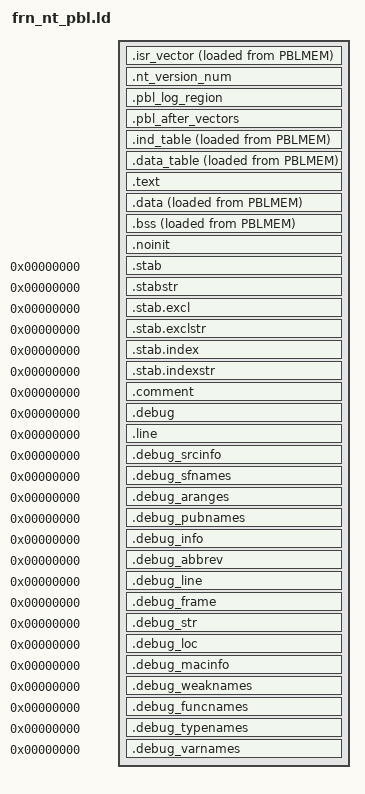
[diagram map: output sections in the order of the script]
/*
*/

/*
 * Memory Spaces Definitions.
 */


INCLUDE frn_nt_bl_cmn.ld



/*
 * Default linker script for Cortex-M
 *
 * To make use of the multi-region initialisations, define
 * OS_INCLUDE_STARTUP_INIT_MULTIPLE_RAM_SECTIONS for the _startup.c file.
 */

/*Neutrino OTP region address start*/
 __OTP_region_st_addr = ORIGIN(OTPMEM);
 __OTP_region_end_addr = ORIGIN(OTPMEM) + LENGTH(OTPMEM);
 __OTP_rfregion_st_addr = ORIGIN(OTPRFMEM);
 __OTP_rfregion_end_addr = ORIGIN(OTPRFMEM) + LENGTH(OTPRFMEM);

 /*RRAM main memory address space*/
 __rram_region_start_addr = ORIGIN(PBLMEM);
 __rram_region_end_address = ORIGIN(PBLMEM) + LENGTH(PBLMEM) + LENGTH(FDTMEM) + LENGTH(SBLAMEM) + LENGTH(RESERVED) + LENGTH(PBL_PATCH) + LENGTH(FSMEM) + LENGTH(CALMEM) + LENGTH(BDFMEM) + LENGTH(REGDBMEM) + LENGTH(RRAMMEM);

 /*FDT address space*/
 __fdt_reg_st_addr = ORIGIN(FDTMEM);
 __fdt_reg_end_addr = ORIGIN(FDTMEM) + LENGTH(FDTMEM);

/*PBL patch function start address*/
 __sec_patch_start = ORIGIN(PBL_PATCH);

/*
 * The '__stack' definition is required by crt0, do not remove it.
 */
_ln_PBL_stack__ = ORIGIN(PBL_RAM) + LENGTH(PBL_RAM);
__PBL_Stack_Size = 0x200 ;
_estack = _ln_PBL_stack__;

PROVIDE ( _PBL_Stack_Size = __PBL_Stack_Size ) ;

__PBL_Stack_Limit = _ln_PBL_stack__  - __PBL_Stack_Size ;

PROVIDE ( _PBL_Stack_Limit = __PBL_Stack_Limit ) ;

 /* config table in ram */
 __config_table = ORIGIN(CONFIG_TABLE);
 __config_table_size = LENGTH(CONFIG_TABLE);

/*
 * Default heap definitions.
 * The heap start immediately after the last statically allocated
 * .sbss/.noinit section, and extends up to the main stack limit.
 */
PROVIDE ( _Heap_Begin = _end_noinit ) ;
PROVIDE ( _Heap_Limit = _ln_PBL_stack__ - __PBL_Stack_Size ) ;


/*
 * The entry point is informative, for debuggers and simulators,
 * since the Cortex-M vector points to it anyway.
 */
ENTRY(nt_boot)


/* Sections Definitions */

SECTIONS
{
	/*
	* For Cortex-M devices, the beginning of the startup code is stored in
	* the .isr_vector section, which goes to FLASH.
	*/
	.isr_vector : ALIGN(4)
	{
		FILL(0xFF)
		__vectors_start = ABSOLUTE(.) ;
		KEEP(*(.pbl_isr_vector))     /* Interrupt vectors */

	} >PBL_RAM AT >PBLMEM

	_ln_RF_start_addr_isr__ = LOADADDR(.isr_vector);
	_ln_RAM_start_addr_isr__ = ADDR(.isr_vector);

	_ln_pbl_isr_size__ = SIZEOF(.isr_vector);

	.nt_version_num : ALIGN(4)
	{
		KEEP(*(.nt_version_num));
	} >PBLMEM

	.pbl_log_region : ALIGN(4)
	{
	    _ln_RAM_ferm_table_addr = ABSOLUTE(.);
        . += 8; /* 4 bytes extra space allocated as reserved */
		__PBL_log_start_addr__ = ABSOLUTE(.) ;
		. += 256 ;
		. = ALIGN(4);
	} > PBL_RAM

	.pbl_after_vectors : ALIGN(4)
	{
		/*
		* This section is here for convenience, to store the
		* startup code at the beginning of the flash area, hoping that
		* this will increase the readability of the listing.
		*/
		*(.pbl_after_vectors .pbl_after_vectors.*) /* Boot code and ISR */

		. = ALIGN(4);

	} >PBLMEM

	.ind_table : ALIGN(4)
	{
		/* This section is for PBL indirection table. This is loaded to RRAM and
		 * copied to RAM during startup.
		 */
		FILL(0xFF)
		__ind_table_start = ABSOLUTE(.) ;
		KEEP(*(.pbl_ind_table))

	} >PBL_RAM AT >PBLMEM

	_ln_RF_start_addr_ind__ = LOADADDR(.ind_table);
	_ln_RAM_start_addr_ind__ = ADDR(.ind_table);
	_ln_pbl_ind_size__ = SIZEOF(.ind_table);

	.data_table : ALIGN(4)
	{
		/* This section is for global data pointer table. This is loaded to RRAM
		 * and copied to RAM during startup.
		 */
		FILL(0xFF)
		__glb_data_table_start = ABSOLUTE(.) ;
		KEEP(*(.glb_data_table))     /* global data table*/

	} >PBL_RAM AT >PBLMEM

	_ln_RF_start_addr_glb_data__ = LOADADDR(.data_table);
	_ln_RAM_start_addr_glb_data__ = ADDR(.data_table);
	_ln_pbl_glb_data_size__ = SIZEOF(.data_table);


	/*
	* The program code is stored in the .text section,
	* which goes to FLASH.
	*/
	.text : ALIGN(4)
	{
		*(.text .text.*) /* all remaining code */
		*(.rodata .rodata.* .constdata .constdata.*) /* read-only data (constants) */
		*(vtable) /* C++ virtual tables */

		KEEP(*(.eh_frame*))

		/*
		* Stub sections generated by the linker, to glue together
		* ARM and Thumb code. .glue_7 is used for ARM code calling
		* Thumb code, and .glue_7t is used for Thumb code calling
		* ARM code. Apparently always generated by the linker, for some
		* architectures, so better leave them here.
		*/
		*(.glue_7)
		*(.glue_7t)

	} >PBLMEM

	/*
	* The initialised data section.
	*
	* The program executes knowing that the data is in the RAM
	* but the loader puts the initial values in the FLASH (inidata).
	* It is one task of the startup to copy the initial values from
	* FLASH to RAM.
	*/
	.data : ALIGN(4)
	{
		FILL(0xFF)

		/* This is used by the startup code to initialise the .data section */

		__data_start__ = . ;
		*(.data_begin .data_begin.*)
		*(.data .data.*)
		*(.data_end .data_end.*)
		. = ALIGN(4);

		/* This is used by the startup code to initialise the .data section */

		__data_end__ = . ;

	} >PBL_RAM AT>PBLMEM
	_ln_RF_start_addr_data__ = LOADADDR(.data);
	_ln_pbl_data_size__ = SIZEOF(.data);

	/*
	* The uninitialised data sections. NOLOAD is used to avoid
	* the "section `.bss' type changed to PROGBITS" warning
	*/


	/* The primary uninitialised data section. */
	.bss (NOLOAD) : ALIGN(4)
	{
		*(.bss_begin .bss_begin.*)

		*(.bss .bss.*)
		*(COMMON)

		*(.bss_end .bss_end.*)
		. = ALIGN(4);
	} >PBL_RAM AT> PBLMEM

	.noinit (NOLOAD) : ALIGN(4)
	{
		_noinit = .;

		*(.noinit .noinit.*)

		. = ALIGN(4) ;
		_end_noinit = .;
	} >PBLMEM


	/* Mandatory to be word aligned, _sbrk assumes this */
	PROVIDE ( end = _end_noinit ); /* was _ebss */
	PROVIDE ( _end = _end_noinit );
	PROVIDE ( __end = _end_noinit );
	PROVIDE ( __end__ = _end_noinit );

	/* After that there are only debugging sections. */

	/* This can remove the debugging information from the standard libraries */


	/* Stabs debugging sections.  */
	.stab          0 : { *(.stab) }
	.stabstr       0 : { *(.stabstr) }
	.stab.excl     0 : { *(.stab.excl) }
	.stab.exclstr  0 : { *(.stab.exclstr) }
	.stab.index    0 : { *(.stab.index) }
	.stab.indexstr 0 : { *(.stab.indexstr) }
	.comment       0 : { *(.comment) }
	/*
	* DWARF debug sections.
	* Symbols in the DWARF debugging sections are relative to the beginning
	* of the section so we begin them at 0.
	*/
	/* DWARF 1 */
	.debug          0 : { *(.debug) }
	.line           0 : { *(.line) }
	/* GNU DWARF 1 extensions */
	.debug_srcinfo  0 : { *(.debug_srcinfo) }
	.debug_sfnames  0 : { *(.debug_sfnames) }
	/* DWARF 1.1 and DWARF 2 */
	.debug_aranges  0 : { *(.debug_aranges) }
	.debug_pubnames 0 : { *(.debug_pubnames) }
	/* DWARF 2 */
	.debug_info     0 : { *(.debug_info .gnu.linkonce.wi.*) }
	.debug_abbrev   0 : { *(.debug_abbrev) }
	.debug_line     0 : { *(.debug_line) }
	.debug_frame    0 : { *(.debug_frame) }
	.debug_str      0 : { *(.debug_str) }
	.debug_loc      0 : { *(.debug_loc) }
	.debug_macinfo  0 : { *(.debug_macinfo) }
	/* SGI/MIPS DWARF 2 extensions */
	.debug_weaknames 0 : { *(.debug_weaknames) }
	.debug_funcnames 0 : { *(.debug_funcnames) }
	.debug_typenames 0 : { *(.debug_typenames) }
	.debug_varnames  0 : { *(.debug_varnames) }
}
